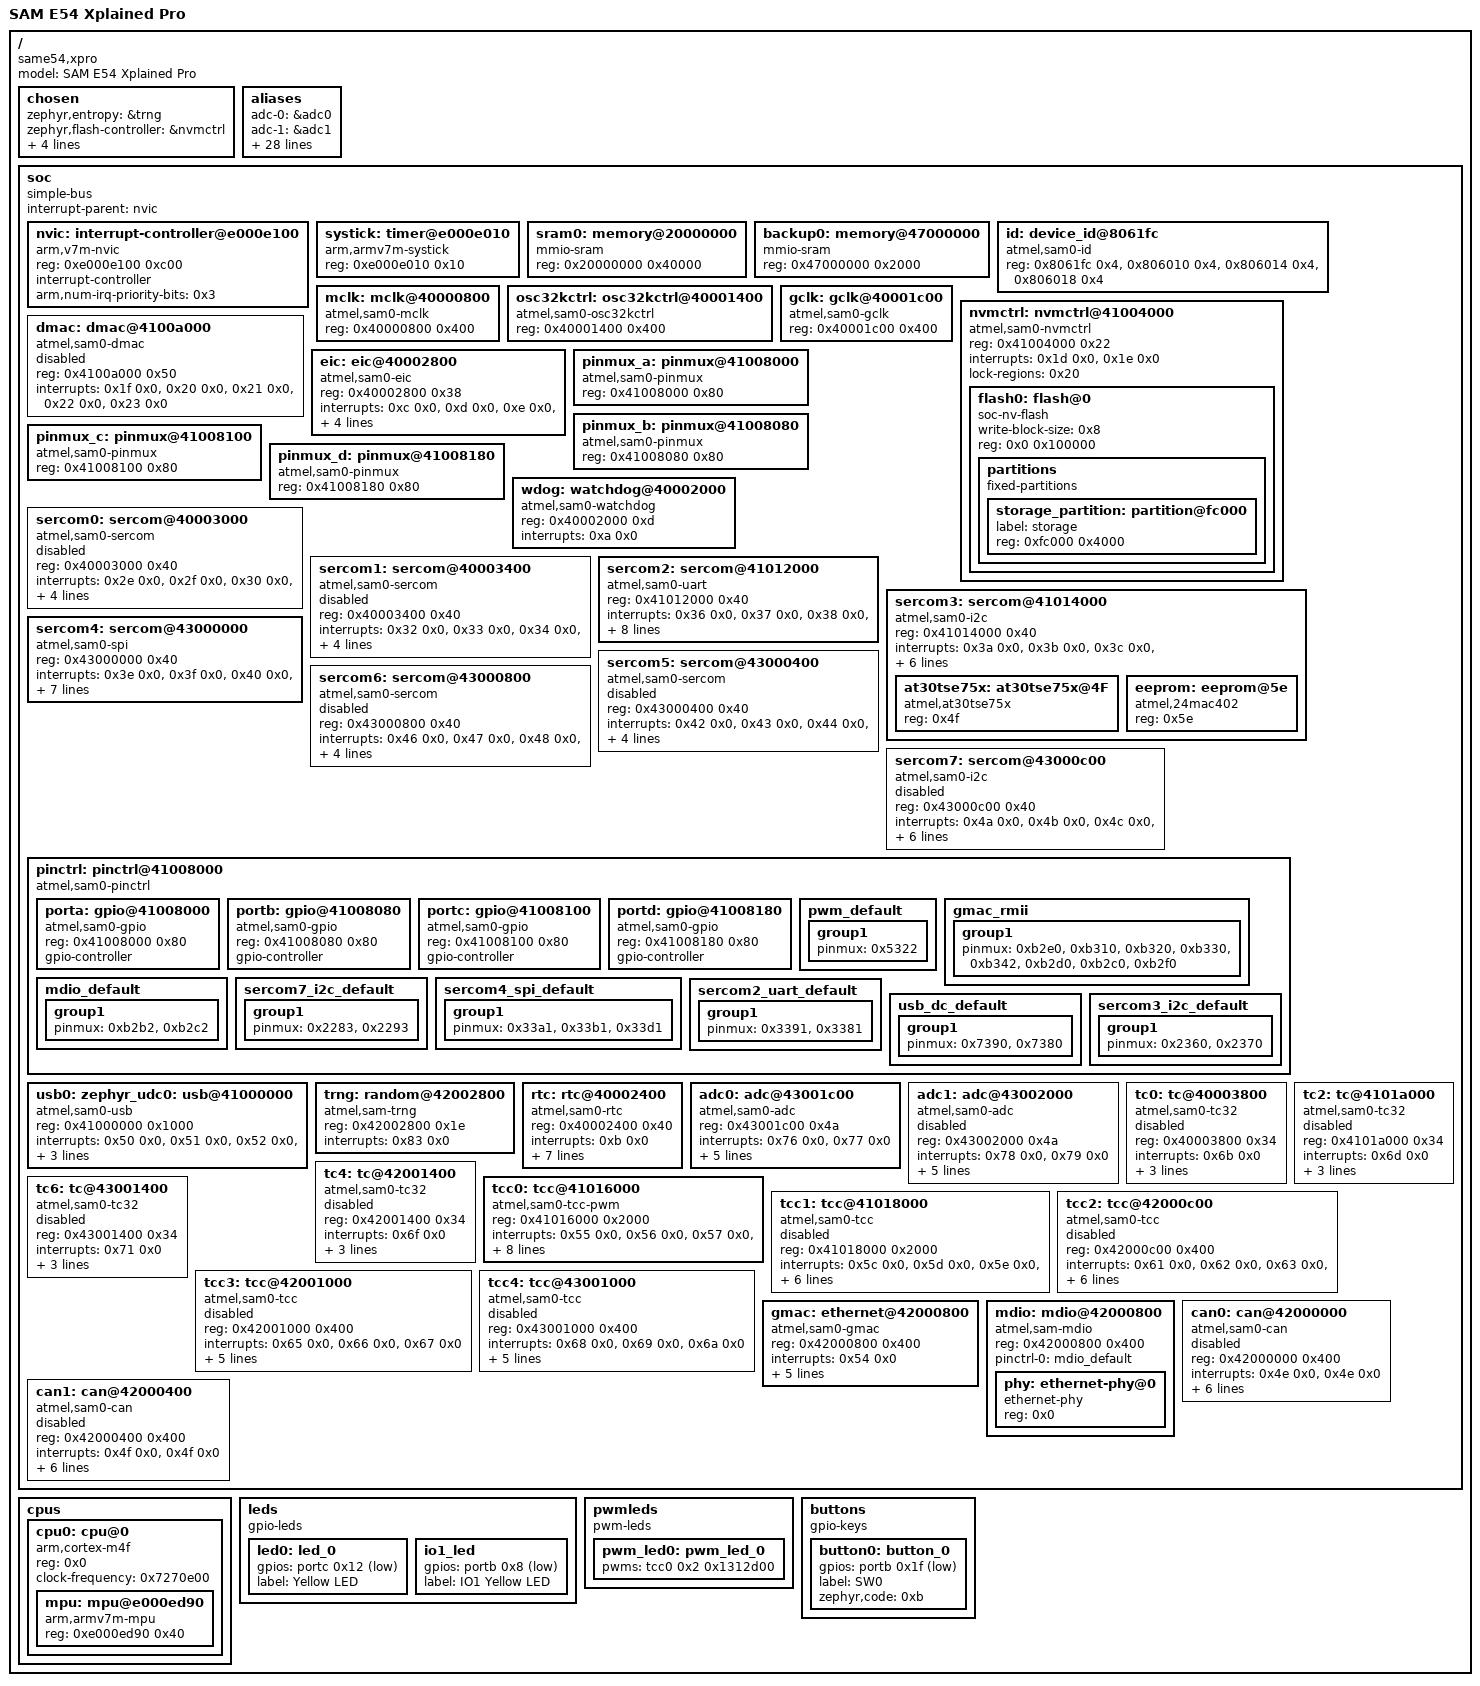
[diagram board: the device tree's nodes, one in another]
/dts-v1/;

/* node '/' defined in zephyr/dts/common/skeleton.dtsi:9 */
/ {
	#address-cells = < 0x1 >;        /* in zephyr/dts/common/skeleton.dtsi:10 */
	#size-cells = < 0x1 >;           /* in zephyr/dts/common/skeleton.dtsi:11 */
	model = "SAM E54 Xplained Pro";  /* in zephyr/boards/atmel/sam0/same54_xpro/same54_xpro.dts:14 */
	compatible = "same54,xpro",
	             "atmel,same54p20a",
	             "atmel,same54";     /* in zephyr/boards/atmel/sam0/same54_xpro/same54_xpro.dts:15 */

	/* node '/chosen' defined in zephyr/dts/common/skeleton.dtsi:12 */
	chosen {
		zephyr,entropy = &trng;             /* in zephyr/dts/arm/atmel/samd5x.dtsi:51 */
		zephyr,flash-controller = &nvmctrl; /* in zephyr/dts/arm/atmel/samd5x.dtsi:52 */
		zephyr,console = &sercom2;          /* in zephyr/boards/atmel/sam0/same54_xpro/same54_xpro.dts:18 */
		zephyr,shell-uart = &sercom2;       /* in zephyr/boards/atmel/sam0/same54_xpro/same54_xpro.dts:19 */
		zephyr,sram = &sram0;               /* in zephyr/boards/atmel/sam0/same54_xpro/same54_xpro.dts:20 */
		zephyr,flash = &flash0;             /* in zephyr/boards/atmel/sam0/same54_xpro/same54_xpro.dts:21 */
	};

	/* node '/aliases' defined in zephyr/dts/common/skeleton.dtsi:13 */
	aliases {
		adc-0 = &adc0;        /* in zephyr/dts/arm/atmel/samd5x.dtsi:16 */
		adc-1 = &adc1;        /* in zephyr/dts/arm/atmel/samd5x.dtsi:17 */
		port-a = &porta;      /* in zephyr/dts/arm/atmel/samd5x.dtsi:19 */
		port-b = &portb;      /* in zephyr/dts/arm/atmel/samd5x.dtsi:20 */
		port-c = &portc;      /* in zephyr/dts/arm/atmel/samd5x.dtsi:21 */
		port-d = &portd;      /* in zephyr/dts/arm/atmel/samd5x.dtsi:22 */
		rtc = &rtc;           /* in zephyr/dts/arm/atmel/samd5x.dtsi:24 */
		sercom-0 = &sercom0;  /* in zephyr/dts/arm/atmel/samd5x.dtsi:26 */
		sercom-1 = &sercom1;  /* in zephyr/dts/arm/atmel/samd5x.dtsi:27 */
		sercom-2 = &sercom2;  /* in zephyr/dts/arm/atmel/samd5x.dtsi:28 */
		sercom-3 = &sercom3;  /* in zephyr/dts/arm/atmel/samd5x.dtsi:29 */
		sercom-4 = &sercom4;  /* in zephyr/dts/arm/atmel/samd5x.dtsi:30 */
		sercom-5 = &sercom5;  /* in zephyr/dts/arm/atmel/samd5x.dtsi:31 */
		sercom-6 = &sercom6;  /* in zephyr/dts/arm/atmel/samd5x.dtsi:32 */
		sercom-7 = &sercom7;  /* in zephyr/dts/arm/atmel/samd5x.dtsi:33 */
		tc-0 = &tc0;          /* in zephyr/dts/arm/atmel/samd5x.dtsi:35 */
		tc-2 = &tc2;          /* in zephyr/dts/arm/atmel/samd5x.dtsi:36 */
		tc-4 = &tc4;          /* in zephyr/dts/arm/atmel/samd5x.dtsi:37 */
		tc-6 = &tc6;          /* in zephyr/dts/arm/atmel/samd5x.dtsi:38 */
		tcc-0 = &tcc0;        /* in zephyr/dts/arm/atmel/samd5x.dtsi:40 */
		tcc-1 = &tcc1;        /* in zephyr/dts/arm/atmel/samd5x.dtsi:41 */
		tcc-2 = &tcc2;        /* in zephyr/dts/arm/atmel/samd5x.dtsi:42 */
		tcc-3 = &tcc3;        /* in zephyr/dts/arm/atmel/samd5x.dtsi:43 */
		tcc-4 = &tcc4;        /* in zephyr/dts/arm/atmel/samd5x.dtsi:44 */
		watchdog0 = &wdog;    /* in zephyr/dts/arm/atmel/samd5x.dtsi:46 */
		led0 = &led0;         /* in zephyr/boards/atmel/sam0/same54_xpro/same54_xpro.dts:26 */
		pwm-led0 = &pwm_led0; /* in zephyr/boards/atmel/sam0/same54_xpro/same54_xpro.dts:27 */
		sw0 = &button0;       /* in zephyr/boards/atmel/sam0/same54_xpro/same54_xpro.dts:28 */
		io1-led = &io1_led;   /* in temperature-web-app/app/boards/same54_xpro.overlay:55 */
		i2c-0 = &sercom3;     /* in temperature-web-app/app/boards/same54_xpro.overlay:56 */
	};

	/* node '/soc' defined in zephyr/dts/arm/armv7-m.dtsi:6 */
	soc {
		#address-cells = < 0x1 >;     /* in zephyr/dts/arm/armv7-m.dtsi:7 */
		#size-cells = < 0x1 >;        /* in zephyr/dts/arm/armv7-m.dtsi:8 */
		compatible = "simple-bus";    /* in zephyr/dts/arm/armv7-m.dtsi:9 */
		interrupt-parent = < &nvic >; /* in zephyr/dts/arm/armv7-m.dtsi:10 */
		ranges;                       /* in zephyr/dts/arm/armv7-m.dtsi:11 */

		/* node '/soc/interrupt-controller@e000e100' defined in zephyr/dts/arm/armv7-m.dtsi:13 */
		nvic: interrupt-controller@e000e100 {
			#address-cells = < 0x1 >;            /* in zephyr/dts/arm/armv7-m.dtsi:14 */
			compatible = "arm,v7m-nvic";         /* in zephyr/dts/arm/armv7-m.dtsi:15 */
			reg = < 0xe000e100 0xc00 >;          /* in zephyr/dts/arm/armv7-m.dtsi:16 */
			interrupt-controller;                /* in zephyr/dts/arm/armv7-m.dtsi:17 */
			#interrupt-cells = < 0x2 >;          /* in zephyr/dts/arm/armv7-m.dtsi:18 */
			arm,num-irq-priority-bits = < 0x3 >; /* in zephyr/dts/arm/atmel/samd5x.dtsi:509 */
			phandle = < 0x1 >;                   /* in zephyr/dts/arm/armv7-m.dtsi:10 */
		};

		/* node '/soc/timer@e000e010' defined in zephyr/dts/arm/armv7-m.dtsi:21 */
		systick: timer@e000e010 {
			compatible = "arm,armv7m-systick"; /* in zephyr/dts/arm/armv7-m.dtsi:22 */
			reg = < 0xe000e010 0x10 >;         /* in zephyr/dts/arm/armv7-m.dtsi:23 */
		};

		/* node '/soc/memory@20000000' defined in zephyr/dts/arm/atmel/samd5x.dtsi:76 */
		sram0: memory@20000000 {
			compatible = "mmio-sram";     /* in zephyr/dts/arm/atmel/samd5x.dtsi:77 */
			reg = < 0x20000000 0x40000 >; /* in zephyr/dts/arm/atmel/same5xx20.dtsi:19 */
		};

		/* node '/soc/memory@47000000' defined in zephyr/dts/arm/atmel/samd5x.dtsi:81 */
		backup0: memory@47000000 {
			compatible = "mmio-sram";    /* in zephyr/dts/arm/atmel/samd5x.dtsi:82 */
			reg = < 0x47000000 0x2000 >; /* in zephyr/dts/arm/atmel/samd5x.dtsi:83 */
		};

		/* node '/soc/device_id@8061fc' defined in zephyr/dts/arm/atmel/samd5x.dtsi:86 */
		id: device_id@8061fc {
			compatible = "atmel,sam0-id"; /* in zephyr/dts/arm/atmel/samd5x.dtsi:87 */
			reg = < 0x8061fc 0x4 >,
			      < 0x806010 0x4 >,
			      < 0x806014 0x4 >,
			      < 0x806018 0x4 >;       /* in zephyr/dts/arm/atmel/samd5x.dtsi:88 */
		};

		/* node '/soc/mclk@40000800' defined in zephyr/dts/arm/atmel/samd5x.dtsi:94 */
		mclk: mclk@40000800 {
			compatible = "atmel,sam0-mclk"; /* in zephyr/dts/arm/atmel/samd5x.dtsi:95 */
			reg = < 0x40000800 0x400 >;     /* in zephyr/dts/arm/atmel/samd5x.dtsi:96 */
			#clock-cells = < 0x2 >;         /* in zephyr/dts/arm/atmel/samd5x.dtsi:98 */
			phandle = < 0x3 >;              /* in zephyr/dts/arm/atmel/samd5x.dtsi:181 */
		};

		/* node '/soc/osc32kctrl@40001400' defined in zephyr/dts/arm/atmel/samd5x.dtsi:101 */
		osc32kctrl: osc32kctrl@40001400 {
			compatible = "atmel,sam0-osc32kctrl";  /* in zephyr/dts/arm/atmel/samd5x.dtsi:102 */
			reg = < 0x40001400 0x400 >;            /* in zephyr/dts/arm/atmel/samd5x.dtsi:103 */
			#clock-cells = < 0x0 >;                /* in zephyr/dts/arm/atmel/samd5x.dtsi:104 */
			#atmel,assigned-clock-cells = < 0x1 >; /* in zephyr/dts/arm/atmel/samd5x.dtsi:105 */
			phandle = < 0x9 >;                     /* in zephyr/dts/arm/atmel/samd5x.dtsi:332 */
		};

		/* node '/soc/gclk@40001c00' defined in zephyr/dts/arm/atmel/samd5x.dtsi:108 */
		gclk: gclk@40001c00 {
			compatible = "atmel,sam0-gclk";        /* in zephyr/dts/arm/atmel/samd5x.dtsi:109 */
			reg = < 0x40001c00 0x400 >;            /* in zephyr/dts/arm/atmel/samd5x.dtsi:110 */
			#clock-cells = < 0x1 >;                /* in zephyr/dts/arm/atmel/samd5x.dtsi:112 */
			#atmel,assigned-clock-cells = < 0x1 >; /* in zephyr/dts/arm/atmel/samd5x.dtsi:113 */
			phandle = < 0x2 >;                     /* in zephyr/dts/arm/atmel/samd5x.dtsi:181 */
		};

		/* node '/soc/nvmctrl@41004000' defined in zephyr/dts/arm/atmel/samd5x.dtsi:116 */
		nvmctrl: nvmctrl@41004000 {
			compatible = "atmel,sam0-nvmctrl"; /* in zephyr/dts/arm/atmel/samd5x.dtsi:117 */
			reg = < 0x41004000 0x22 >;         /* in zephyr/dts/arm/atmel/samd5x.dtsi:118 */
			interrupts = < 0x1d 0x0 >,
			             < 0x1e 0x0 >;         /* in zephyr/dts/arm/atmel/samd5x.dtsi:119 */
			#address-cells = < 0x1 >;          /* in zephyr/dts/arm/atmel/samd5x.dtsi:121 */
			#size-cells = < 0x1 >;             /* in zephyr/dts/arm/atmel/samd5x.dtsi:122 */
			lock-regions = < 0x20 >;           /* in zephyr/dts/arm/atmel/samd5x.dtsi:124 */

			/* node '/soc/nvmctrl@41004000/flash@0' defined in zephyr/dts/arm/atmel/samd5x.dtsi:126 */
			flash0: flash@0 {
				compatible = "soc-nv-flash"; /* in zephyr/dts/arm/atmel/samd5x.dtsi:127 */
				write-block-size = < 0x8 >;  /* in zephyr/dts/arm/atmel/samd5x.dtsi:129 */
				reg = < 0x0 0x100000 >;      /* in zephyr/dts/arm/atmel/same5xx20.dtsi:14 */

				/* node '/soc/nvmctrl@41004000/flash@0/partitions' defined in zephyr/boards/atmel/sam0/same54_xpro/same54_xpro.dts:156 */
				partitions {
					compatible = "fixed-partitions"; /* in zephyr/boards/atmel/sam0/same54_xpro/same54_xpro.dts:157 */
					#address-cells = < 0x1 >;        /* in zephyr/boards/atmel/sam0/same54_xpro/same54_xpro.dts:158 */
					#size-cells = < 0x1 >;           /* in zephyr/boards/atmel/sam0/same54_xpro/same54_xpro.dts:159 */

					/* node '/soc/nvmctrl@41004000/flash@0/partitions/partition@fc000' defined in zephyr/boards/atmel/sam0/same54_xpro/same54_xpro.dts:166 */
					storage_partition: partition@fc000 {
						label = "storage";        /* in zephyr/boards/atmel/sam0/same54_xpro/same54_xpro.dts:167 */
						reg = < 0xfc000 0x4000 >; /* in zephyr/boards/atmel/sam0/same54_xpro/same54_xpro.dts:168 */
					};
				};
			};
		};

		/* node '/soc/dmac@4100a000' defined in zephyr/dts/arm/atmel/samd5x.dtsi:133 */
		dmac: dmac@4100a000 {
			compatible = "atmel,sam0-dmac"; /* in zephyr/dts/arm/atmel/samd5x.dtsi:134 */
			reg = < 0x4100a000 0x50 >;      /* in zephyr/dts/arm/atmel/samd5x.dtsi:135 */
			interrupts = < 0x1f 0x0 >,
			             < 0x20 0x0 >,
			             < 0x21 0x0 >,
			             < 0x22 0x0 >,
			             < 0x23 0x0 >;      /* in zephyr/dts/arm/atmel/samd5x.dtsi:136 */
			status = "disabled";            /* in zephyr/dts/arm/atmel/samd5x.dtsi:137 */
			#dma-cells = < 0x2 >;           /* in zephyr/dts/arm/atmel/samd5x.dtsi:139 */
		};

		/* node '/soc/eic@40002800' defined in zephyr/dts/arm/atmel/samd5x.dtsi:142 */
		eic: eic@40002800 {
			compatible = "atmel,sam0-eic"; /* in zephyr/dts/arm/atmel/samd5x.dtsi:143 */
			reg = < 0x40002800 0x38 >;     /* in zephyr/dts/arm/atmel/samd5x.dtsi:144 */
			interrupts = < 0xc 0x0 >,
			             < 0xd 0x0 >,
			             < 0xe 0x0 >,
			             < 0xf 0x0 >,
			             < 0x10 0x0 >,
			             < 0x11 0x0 >,
			             < 0x12 0x0 >,
			             < 0x13 0x0 >,
			             < 0x14 0x0 >,
			             < 0x15 0x0 >,
			             < 0x16 0x0 >,
			             < 0x17 0x0 >,
			             < 0x18 0x0 >,
			             < 0x19 0x0 >,
			             < 0x1a 0x0 >,
			             < 0x1b 0x0 >;     /* in zephyr/dts/arm/atmel/samd5x.dtsi:145 */
		};

		/* node '/soc/pinmux@41008000' defined in zephyr/dts/arm/atmel/samd5x.dtsi:151 */
		pinmux_a: pinmux@41008000 {
			compatible = "atmel,sam0-pinmux"; /* in zephyr/dts/arm/atmel/samd5x.dtsi:152 */
			reg = < 0x41008000 0x80 >;        /* in zephyr/dts/arm/atmel/samd5x.dtsi:153 */
		};

		/* node '/soc/pinmux@41008080' defined in zephyr/dts/arm/atmel/samd5x.dtsi:156 */
		pinmux_b: pinmux@41008080 {
			compatible = "atmel,sam0-pinmux"; /* in zephyr/dts/arm/atmel/samd5x.dtsi:157 */
			reg = < 0x41008080 0x80 >;        /* in zephyr/dts/arm/atmel/samd5x.dtsi:158 */
		};

		/* node '/soc/pinmux@41008100' defined in zephyr/dts/arm/atmel/samd5x.dtsi:161 */
		pinmux_c: pinmux@41008100 {
			compatible = "atmel,sam0-pinmux"; /* in zephyr/dts/arm/atmel/samd5x.dtsi:162 */
			reg = < 0x41008100 0x80 >;        /* in zephyr/dts/arm/atmel/samd5x.dtsi:163 */
		};

		/* node '/soc/pinmux@41008180' defined in zephyr/dts/arm/atmel/samd5x.dtsi:166 */
		pinmux_d: pinmux@41008180 {
			compatible = "atmel,sam0-pinmux"; /* in zephyr/dts/arm/atmel/samd5x.dtsi:167 */
			reg = < 0x41008180 0x80 >;        /* in zephyr/dts/arm/atmel/samd5x.dtsi:168 */
		};

		/* node '/soc/watchdog@40002000' defined in zephyr/dts/arm/atmel/samd5x.dtsi:171 */
		wdog: watchdog@40002000 {
			compatible = "atmel,sam0-watchdog"; /* in zephyr/dts/arm/atmel/samd5x.dtsi:172 */
			reg = < 0x40002000 0xd >;           /* in zephyr/dts/arm/atmel/samd5x.dtsi:173 */
			interrupts = < 0xa 0x0 >;           /* in zephyr/dts/arm/atmel/samd5x.dtsi:174 */
		};

		/* node '/soc/sercom@40003000' defined in zephyr/dts/arm/atmel/samd5x.dtsi:177 */
		sercom0: sercom@40003000 {
			compatible = "atmel,sam0-sercom";      /* in zephyr/dts/arm/atmel/samd5x.dtsi:178 */
			reg = < 0x40003000 0x40 >;             /* in zephyr/dts/arm/atmel/samd5x.dtsi:179 */
			interrupts = < 0x2e 0x0 >,
			             < 0x2f 0x0 >,
			             < 0x30 0x0 >,
			             < 0x31 0x0 >;             /* in zephyr/dts/arm/atmel/samd5x.dtsi:180 */
			clocks = < &gclk 0x7 >,
			         < &mclk 0x14 0xc >;           /* in zephyr/dts/arm/atmel/samd5x.dtsi:181 */
			clock-names = "GCLK",
			              "MCLK";                  /* in zephyr/dts/arm/atmel/samd5x.dtsi:182 */
			atmel,assigned-clocks = < &gclk 0x0 >; /* in zephyr/dts/arm/atmel/samd5x.dtsi:183 */
			atmel,assigned-clock-names = "GCLK";   /* in zephyr/dts/arm/atmel/samd5x.dtsi:184 */
			status = "disabled";                   /* in zephyr/dts/arm/atmel/samd5x.dtsi:185 */
		};

		/* node '/soc/sercom@40003400' defined in zephyr/dts/arm/atmel/samd5x.dtsi:188 */
		sercom1: sercom@40003400 {
			compatible = "atmel,sam0-sercom";      /* in zephyr/dts/arm/atmel/samd5x.dtsi:189 */
			reg = < 0x40003400 0x40 >;             /* in zephyr/dts/arm/atmel/samd5x.dtsi:190 */
			interrupts = < 0x32 0x0 >,
			             < 0x33 0x0 >,
			             < 0x34 0x0 >,
			             < 0x35 0x0 >;             /* in zephyr/dts/arm/atmel/samd5x.dtsi:191 */
			clocks = < &gclk 0x8 >,
			         < &mclk 0x14 0xd >;           /* in zephyr/dts/arm/atmel/samd5x.dtsi:192 */
			clock-names = "GCLK",
			              "MCLK";                  /* in zephyr/dts/arm/atmel/samd5x.dtsi:193 */
			atmel,assigned-clocks = < &gclk 0x0 >; /* in zephyr/dts/arm/atmel/samd5x.dtsi:194 */
			atmel,assigned-clock-names = "GCLK";   /* in zephyr/dts/arm/atmel/samd5x.dtsi:195 */
			status = "disabled";                   /* in zephyr/dts/arm/atmel/samd5x.dtsi:196 */
		};

		/* node '/soc/sercom@41012000' defined in zephyr/dts/arm/atmel/samd5x.dtsi:199 */
		sercom2: sercom@41012000 {
			reg = < 0x41012000 0x40 >;             /* in zephyr/dts/arm/atmel/samd5x.dtsi:201 */
			interrupts = < 0x36 0x0 >,
			             < 0x37 0x0 >,
			             < 0x38 0x0 >,
			             < 0x39 0x0 >;             /* in zephyr/dts/arm/atmel/samd5x.dtsi:202 */
			clocks = < &gclk 0x17 >,
			         < &mclk 0x18 0x9 >;           /* in zephyr/dts/arm/atmel/samd5x.dtsi:203 */
			clock-names = "GCLK",
			              "MCLK";                  /* in zephyr/dts/arm/atmel/samd5x.dtsi:204 */
			atmel,assigned-clocks = < &gclk 0x0 >; /* in zephyr/dts/arm/atmel/samd5x.dtsi:205 */
			atmel,assigned-clock-names = "GCLK";   /* in zephyr/dts/arm/atmel/samd5x.dtsi:206 */
			status = "okay";                       /* in zephyr/boards/atmel/sam0/same54_xpro/same54_xpro.dts:81 */
			compatible = "atmel,sam0-uart";        /* in zephyr/boards/atmel/sam0/same54_xpro/same54_xpro.dts:82 */
			current-speed = < 0x1c200 >;           /* in zephyr/boards/atmel/sam0/same54_xpro/same54_xpro.dts:83 */
			rxpo = < 0x1 >;                        /* in zephyr/boards/atmel/sam0/same54_xpro/same54_xpro.dts:84 */
			txpo = < 0x0 >;                        /* in zephyr/boards/atmel/sam0/same54_xpro/same54_xpro.dts:85 */
			#address-cells = < 0x1 >;              /* in zephyr/boards/atmel/sam0/same54_xpro/same54_xpro.dts:86 */
			#size-cells = < 0x0 >;                 /* in zephyr/boards/atmel/sam0/same54_xpro/same54_xpro.dts:87 */
			pinctrl-0 = < &sercom2_uart_default >; /* in zephyr/boards/atmel/sam0/same54_xpro/same54_xpro.dts:89 */
			pinctrl-names = "default";             /* in zephyr/boards/atmel/sam0/same54_xpro/same54_xpro.dts:90 */
		};

		/* node '/soc/sercom@41014000' defined in zephyr/dts/arm/atmel/samd5x.dtsi:210 */
		sercom3: sercom@41014000 {
			reg = < 0x41014000 0x40 >;             /* in zephyr/dts/arm/atmel/samd5x.dtsi:212 */
			interrupts = < 0x3a 0x0 >,
			             < 0x3b 0x0 >,
			             < 0x3c 0x0 >,
			             < 0x3d 0x0 >;             /* in zephyr/dts/arm/atmel/samd5x.dtsi:213 */
			clocks = < &gclk 0x18 >,
			         < &mclk 0x18 0xa >;           /* in zephyr/dts/arm/atmel/samd5x.dtsi:214 */
			clock-names = "GCLK",
			              "MCLK";                  /* in zephyr/dts/arm/atmel/samd5x.dtsi:215 */
			atmel,assigned-clocks = < &gclk 0x0 >; /* in zephyr/dts/arm/atmel/samd5x.dtsi:216 */
			atmel,assigned-clock-names = "GCLK";   /* in zephyr/dts/arm/atmel/samd5x.dtsi:217 */
			status = "okay";                       /* in temperature-web-app/app/boards/same54_xpro.overlay:22 */
			compatible = "atmel,sam0-i2c";         /* in temperature-web-app/app/boards/same54_xpro.overlay:23 */
			clock-frequency = < 0x61a80 >;         /* in temperature-web-app/app/boards/same54_xpro.overlay:24 */
			#address-cells = < 0x1 >;              /* in temperature-web-app/app/boards/same54_xpro.overlay:25 */
			#size-cells = < 0x0 >;                 /* in temperature-web-app/app/boards/same54_xpro.overlay:26 */
			pinctrl-0 = < &sercom3_i2c_default >;  /* in temperature-web-app/app/boards/same54_xpro.overlay:27 */
			pinctrl-names = "default";             /* in temperature-web-app/app/boards/same54_xpro.overlay:28 */

			/* node '/soc/sercom@41014000/at30tse75x@4F' defined in temperature-web-app/app/boards/same54_xpro.overlay:31 */
			at30tse75x: at30tse75x@4F {
				compatible = "atmel,at30tse75x"; /* in temperature-web-app/app/boards/same54_xpro.overlay:32 */
				reg = < 0x4f >;                  /* in temperature-web-app/app/boards/same54_xpro.overlay:33 */
			};

			/* node '/soc/sercom@41014000/eeprom@5e' defined in temperature-web-app/app/boards/same54_xpro.overlay:36 */
			eeprom: eeprom@5e {
				compatible = "atmel,24mac402"; /* in temperature-web-app/app/boards/same54_xpro.overlay:37 */
				reg = < 0x5e >;                /* in temperature-web-app/app/boards/same54_xpro.overlay:38 */
				phandle = < 0xc >;             /* in zephyr/boards/atmel/sam0/same54_xpro/same54_xpro.dts:138 */
			};
		};

		/* node '/soc/sercom@43000000' defined in zephyr/dts/arm/atmel/samd5x.dtsi:221 */
		sercom4: sercom@43000000 {
			reg = < 0x43000000 0x40 >;             /* in zephyr/dts/arm/atmel/samd5x.dtsi:223 */
			interrupts = < 0x3e 0x0 >,
			             < 0x3f 0x0 >,
			             < 0x40 0x0 >,
			             < 0x41 0x0 >;             /* in zephyr/dts/arm/atmel/samd5x.dtsi:224 */
			clocks = < &gclk 0x22 >,
			         < &mclk 0x20 0x0 >;           /* in zephyr/dts/arm/atmel/samd5x.dtsi:225 */
			clock-names = "GCLK",
			              "MCLK";                  /* in zephyr/dts/arm/atmel/samd5x.dtsi:226 */
			atmel,assigned-clocks = < &gclk 0x0 >; /* in zephyr/dts/arm/atmel/samd5x.dtsi:227 */
			atmel,assigned-clock-names = "GCLK";   /* in zephyr/dts/arm/atmel/samd5x.dtsi:228 */
			status = "okay";                       /* in zephyr/boards/atmel/sam0/same54_xpro/same54_xpro.dts:94 */
			compatible = "atmel,sam0-spi";         /* in zephyr/boards/atmel/sam0/same54_xpro/same54_xpro.dts:95 */
			dipo = < 0x3 >;                        /* in zephyr/boards/atmel/sam0/same54_xpro/same54_xpro.dts:96 */
			dopo = < 0x0 >;                        /* in zephyr/boards/atmel/sam0/same54_xpro/same54_xpro.dts:97 */
			#address-cells = < 0x1 >;              /* in zephyr/boards/atmel/sam0/same54_xpro/same54_xpro.dts:98 */
			#size-cells = < 0x0 >;                 /* in zephyr/boards/atmel/sam0/same54_xpro/same54_xpro.dts:99 */
			pinctrl-0 = < &sercom4_spi_default >;  /* in zephyr/boards/atmel/sam0/same54_xpro/same54_xpro.dts:101 */
			pinctrl-names = "default";             /* in zephyr/boards/atmel/sam0/same54_xpro/same54_xpro.dts:102 */
		};

		/* node '/soc/sercom@43000400' defined in zephyr/dts/arm/atmel/samd5x.dtsi:232 */
		sercom5: sercom@43000400 {
			compatible = "atmel,sam0-sercom";      /* in zephyr/dts/arm/atmel/samd5x.dtsi:233 */
			reg = < 0x43000400 0x40 >;             /* in zephyr/dts/arm/atmel/samd5x.dtsi:234 */
			interrupts = < 0x42 0x0 >,
			             < 0x43 0x0 >,
			             < 0x44 0x0 >,
			             < 0x45 0x0 >;             /* in zephyr/dts/arm/atmel/samd5x.dtsi:235 */
			clocks = < &gclk 0x23 >,
			         < &mclk 0x20 0x1 >;           /* in zephyr/dts/arm/atmel/samd5x.dtsi:236 */
			clock-names = "GCLK",
			              "MCLK";                  /* in zephyr/dts/arm/atmel/samd5x.dtsi:237 */
			atmel,assigned-clocks = < &gclk 0x0 >; /* in zephyr/dts/arm/atmel/samd5x.dtsi:238 */
			atmel,assigned-clock-names = "GCLK";   /* in zephyr/dts/arm/atmel/samd5x.dtsi:239 */
			status = "disabled";                   /* in zephyr/dts/arm/atmel/samd5x.dtsi:240 */
		};

		/* node '/soc/sercom@43000800' defined in zephyr/dts/arm/atmel/samd5x.dtsi:243 */
		sercom6: sercom@43000800 {
			compatible = "atmel,sam0-sercom";      /* in zephyr/dts/arm/atmel/samd5x.dtsi:244 */
			reg = < 0x43000800 0x40 >;             /* in zephyr/dts/arm/atmel/samd5x.dtsi:245 */
			interrupts = < 0x46 0x0 >,
			             < 0x47 0x0 >,
			             < 0x48 0x0 >,
			             < 0x49 0x0 >;             /* in zephyr/dts/arm/atmel/samd5x.dtsi:246 */
			clocks = < &gclk 0x24 >,
			         < &mclk 0x20 0x2 >;           /* in zephyr/dts/arm/atmel/samd5x.dtsi:247 */
			clock-names = "GCLK",
			              "MCLK";                  /* in zephyr/dts/arm/atmel/samd5x.dtsi:248 */
			atmel,assigned-clocks = < &gclk 0x0 >; /* in zephyr/dts/arm/atmel/samd5x.dtsi:249 */
			atmel,assigned-clock-names = "GCLK";   /* in zephyr/dts/arm/atmel/samd5x.dtsi:250 */
			status = "disabled";                   /* in zephyr/dts/arm/atmel/samd5x.dtsi:251 */
		};

		/* node '/soc/sercom@43000c00' defined in zephyr/dts/arm/atmel/samd5x.dtsi:254 */
		sercom7: sercom@43000c00 {
			reg = < 0x43000c00 0x40 >;             /* in zephyr/dts/arm/atmel/samd5x.dtsi:256 */
			interrupts = < 0x4a 0x0 >,
			             < 0x4b 0x0 >,
			             < 0x4c 0x0 >,
			             < 0x4d 0x0 >;             /* in zephyr/dts/arm/atmel/samd5x.dtsi:257 */
			clocks = < &gclk 0x25 >,
			         < &mclk 0x20 0x3 >;           /* in zephyr/dts/arm/atmel/samd5x.dtsi:258 */
			clock-names = "GCLK",
			              "MCLK";                  /* in zephyr/dts/arm/atmel/samd5x.dtsi:259 */
			atmel,assigned-clocks = < &gclk 0x0 >; /* in zephyr/dts/arm/atmel/samd5x.dtsi:260 */
			atmel,assigned-clock-names = "GCLK";   /* in zephyr/dts/arm/atmel/samd5x.dtsi:261 */
			clock-frequency = < 0x61a80 >;         /* in zephyr/boards/atmel/sam0/same54_xpro/same54_xpro.dts:108 */
			#address-cells = < 0x1 >;              /* in zephyr/boards/atmel/sam0/same54_xpro/same54_xpro.dts:109 */
			#size-cells = < 0x0 >;                 /* in zephyr/boards/atmel/sam0/same54_xpro/same54_xpro.dts:110 */
			pinctrl-0 = < &sercom7_i2c_default >;  /* in zephyr/boards/atmel/sam0/same54_xpro/same54_xpro.dts:112 */
			pinctrl-names = "default";             /* in zephyr/boards/atmel/sam0/same54_xpro/same54_xpro.dts:113 */
			status = "disabled";                   /* in temperature-web-app/app/boards/same54_xpro.overlay:3 */
			compatible = "atmel,sam0-i2c";         /* in temperature-web-app/app/boards/same54_xpro.overlay:4 */
		};

		/* node '/soc/pinctrl@41008000' defined in zephyr/dts/arm/atmel/samd5x.dtsi:265 */
		pinctrl: pinctrl@41008000 {
			compatible = "atmel,sam0-pinctrl";        /* in zephyr/dts/arm/atmel/samd5x.dtsi:266 */
			ranges = < 0x41008000 0x41008000 0x200 >; /* in zephyr/dts/arm/atmel/samd5x.dtsi:267 */
			#address-cells = < 0x1 >;                 /* in zephyr/dts/arm/atmel/samd5x.dtsi:269 */
			#size-cells = < 0x1 >;                    /* in zephyr/dts/arm/atmel/samd5x.dtsi:270 */

			/* node '/soc/pinctrl@41008000/gpio@41008000' defined in zephyr/dts/arm/atmel/samd5x.dtsi:272 */
			porta: gpio@41008000 {
				compatible = "atmel,sam0-gpio"; /* in zephyr/dts/arm/atmel/samd5x.dtsi:273 */
				reg = < 0x41008000 0x80 >;      /* in zephyr/dts/arm/atmel/samd5x.dtsi:274 */
				#atmel,pin-cells = < 0x2 >;     /* in zephyr/dts/arm/atmel/samd5x.dtsi:276 */
				#gpio-cells = < 0x2 >;          /* in zephyr/dts/arm/atmel/samd5x.dtsi:277 */
				gpio-controller;                /* in zephyr/dts/arm/atmel/samd5x.dtsi:279 */
			};

			/* node '/soc/pinctrl@41008000/gpio@41008080' defined in zephyr/dts/arm/atmel/samd5x.dtsi:282 */
			portb: gpio@41008080 {
				compatible = "atmel,sam0-gpio"; /* in zephyr/dts/arm/atmel/samd5x.dtsi:283 */
				reg = < 0x41008080 0x80 >;      /* in zephyr/dts/arm/atmel/samd5x.dtsi:284 */
				#atmel,pin-cells = < 0x2 >;     /* in zephyr/dts/arm/atmel/samd5x.dtsi:286 */
				#gpio-cells = < 0x2 >;          /* in zephyr/dts/arm/atmel/samd5x.dtsi:287 */
				gpio-controller;                /* in zephyr/dts/arm/atmel/samd5x.dtsi:289 */
				phandle = < 0x10 >;             /* in temperature-web-app/app/boards/same54_xpro.overlay:48 */
			};

			/* node '/soc/pinctrl@41008000/gpio@41008100' defined in zephyr/dts/arm/atmel/samd5x.dtsi:292 */
			portc: gpio@41008100 {
				compatible = "atmel,sam0-gpio"; /* in zephyr/dts/arm/atmel/samd5x.dtsi:293 */
				reg = < 0x41008100 0x80 >;      /* in zephyr/dts/arm/atmel/samd5x.dtsi:294 */
				#atmel,pin-cells = < 0x2 >;     /* in zephyr/dts/arm/atmel/samd5x.dtsi:296 */
				#gpio-cells = < 0x2 >;          /* in zephyr/dts/arm/atmel/samd5x.dtsi:297 */
				gpio-controller;                /* in zephyr/dts/arm/atmel/samd5x.dtsi:299 */
				phandle = < 0xf >;              /* in zephyr/boards/atmel/sam0/same54_xpro/same54_xpro.dts:35 */
			};

			/* node '/soc/pinctrl@41008000/gpio@41008180' defined in zephyr/dts/arm/atmel/samd5x.dtsi:302 */
			portd: gpio@41008180 {
				compatible = "atmel,sam0-gpio"; /* in zephyr/dts/arm/atmel/samd5x.dtsi:303 */
				reg = < 0x41008180 0x80 >;      /* in zephyr/dts/arm/atmel/samd5x.dtsi:304 */
				#atmel,pin-cells = < 0x2 >;     /* in zephyr/dts/arm/atmel/samd5x.dtsi:306 */
				#gpio-cells = < 0x2 >;          /* in zephyr/dts/arm/atmel/samd5x.dtsi:307 */
				gpio-controller;                /* in zephyr/dts/arm/atmel/samd5x.dtsi:309 */
			};

			/* node '/soc/pinctrl@41008000/pwm_default' defined in zephyr/boards/atmel/sam0/same54_xpro/same54_xpro-pinctrl.dtsi:9 */
			pwm_default: pwm_default {
				phandle = < 0xa >; /* in zephyr/boards/atmel/sam0/same54_xpro/same54_xpro.dts:68 */

				/* node '/soc/pinctrl@41008000/pwm_default/group1' defined in zephyr/boards/atmel/sam0/same54_xpro/same54_xpro-pinctrl.dtsi:10 */
				group1 {
					pinmux = < 0x5322 >; /* in zephyr/boards/atmel/sam0/same54_xpro/same54_xpro-pinctrl.dtsi:11 */
				};
			};

			/* node '/soc/pinctrl@41008000/gmac_rmii' defined in zephyr/boards/atmel/sam0/same54_xpro/same54_xpro-pinctrl.dtsi:15 */
			gmac_rmii: gmac_rmii {
				phandle = < 0xb >; /* in zephyr/boards/atmel/sam0/same54_xpro/same54_xpro.dts:135 */

				/* node '/soc/pinctrl@41008000/gmac_rmii/group1' defined in zephyr/boards/atmel/sam0/same54_xpro/same54_xpro-pinctrl.dtsi:16 */
				group1 {
					pinmux = < 0xb2e0 >,
					         < 0xb310 >,
					         < 0xb320 >,
					         < 0xb330 >,
					         < 0xb342 >,
					         < 0xb2d0 >,
					         < 0xb2c0 >,
					         < 0xb2f0 >; /* in zephyr/boards/atmel/sam0/same54_xpro/same54_xpro-pinctrl.dtsi:17 */
				};
			};

			/* node '/soc/pinctrl@41008000/mdio_default' defined in zephyr/boards/atmel/sam0/same54_xpro/same54_xpro-pinctrl.dtsi:28 */
			mdio_default: mdio_default {
				phandle = < 0xe >; /* in zephyr/boards/atmel/sam0/same54_xpro/same54_xpro.dts:145 */

				/* node '/soc/pinctrl@41008000/mdio_default/group1' defined in zephyr/boards/atmel/sam0/same54_xpro/same54_xpro-pinctrl.dtsi:29 */
				group1 {
					pinmux = < 0xb2b2 >,
					         < 0xb2c2 >; /* in zephyr/boards/atmel/sam0/same54_xpro/same54_xpro-pinctrl.dtsi:30 */
				};
			};

			/* node '/soc/pinctrl@41008000/sercom7_i2c_default' defined in zephyr/boards/atmel/sam0/same54_xpro/same54_xpro-pinctrl.dtsi:35 */
			sercom7_i2c_default: sercom7_i2c_default {
				phandle = < 0x7 >; /* in zephyr/boards/atmel/sam0/same54_xpro/same54_xpro.dts:112 */

				/* node '/soc/pinctrl@41008000/sercom7_i2c_default/group1' defined in zephyr/boards/atmel/sam0/same54_xpro/same54_xpro-pinctrl.dtsi:36 */
				group1 {
					pinmux = < 0x2283 >,
					         < 0x2293 >; /* in zephyr/boards/atmel/sam0/same54_xpro/same54_xpro-pinctrl.dtsi:37 */
				};
			};

			/* node '/soc/pinctrl@41008000/sercom4_spi_default' defined in zephyr/boards/atmel/sam0/same54_xpro/same54_xpro-pinctrl.dtsi:42 */
			sercom4_spi_default: sercom4_spi_default {
				phandle = < 0x6 >; /* in zephyr/boards/atmel/sam0/same54_xpro/same54_xpro.dts:101 */

				/* node '/soc/pinctrl@41008000/sercom4_spi_default/group1' defined in zephyr/boards/atmel/sam0/same54_xpro/same54_xpro-pinctrl.dtsi:43 */
				group1 {
					pinmux = < 0x33a1 >,
					         < 0x33b1 >,
					         < 0x33d1 >; /* in zephyr/boards/atmel/sam0/same54_xpro/same54_xpro-pinctrl.dtsi:44 */
				};
			};

			/* node '/soc/pinctrl@41008000/sercom2_uart_default' defined in zephyr/boards/atmel/sam0/same54_xpro/same54_xpro-pinctrl.dtsi:50 */
			sercom2_uart_default: sercom2_uart_default {
				phandle = < 0x4 >; /* in zephyr/boards/atmel/sam0/same54_xpro/same54_xpro.dts:89 */

				/* node '/soc/pinctrl@41008000/sercom2_uart_default/group1' defined in zephyr/boards/atmel/sam0/same54_xpro/same54_xpro-pinctrl.dtsi:51 */
				group1 {
					pinmux = < 0x3391 >,
					         < 0x3381 >; /* in zephyr/boards/atmel/sam0/same54_xpro/same54_xpro-pinctrl.dtsi:52 */
				};
			};

			/* node '/soc/pinctrl@41008000/usb_dc_default' defined in zephyr/boards/atmel/sam0/same54_xpro/same54_xpro-pinctrl.dtsi:57 */
			usb_dc_default: usb_dc_default {
				phandle = < 0x8 >; /* in zephyr/boards/atmel/sam0/same54_xpro/same54_xpro.dts:128 */

				/* node '/soc/pinctrl@41008000/usb_dc_default/group1' defined in zephyr/boards/atmel/sam0/same54_xpro/same54_xpro-pinctrl.dtsi:58 */
				group1 {
					pinmux = < 0x7390 >,
					         < 0x7380 >; /* in zephyr/boards/atmel/sam0/same54_xpro/same54_xpro-pinctrl.dtsi:59 */
				};
			};

			/* node '/soc/pinctrl@41008000/sercom3_i2c_default' defined in temperature-web-app/app/boards/same54_xpro.overlay:11 */
			sercom3_i2c_default: sercom3_i2c_default {
				phandle = < 0x5 >; /* in temperature-web-app/app/boards/same54_xpro.overlay:27 */

				/* node '/soc/pinctrl@41008000/sercom3_i2c_default/group1' defined in temperature-web-app/app/boards/same54_xpro.overlay:12 */
				group1 {
					pinmux = < 0x2360 >,
					         < 0x2370 >; /* in temperature-web-app/app/boards/same54_xpro.overlay:13 */
				};
			};
		};

		/* node '/soc/usb@41000000' defined in zephyr/dts/arm/atmel/samd5x.dtsi:313 */
		usb0: zephyr_udc0: usb@41000000 {
			compatible = "atmel,sam0-usb";   /* in zephyr/dts/arm/atmel/samd5x.dtsi:314 */
			reg = < 0x41000000 0x1000 >;     /* in zephyr/dts/arm/atmel/samd5x.dtsi:315 */
			interrupts = < 0x50 0x0 >,
			             < 0x51 0x0 >,
			             < 0x52 0x0 >,
			             < 0x53 0x0 >;       /* in zephyr/dts/arm/atmel/samd5x.dtsi:316 */
			num-bidir-endpoints = < 0x8 >;   /* in zephyr/dts/arm/atmel/samd5x.dtsi:319 */
			status = "okay";                 /* in zephyr/boards/atmel/sam0/same54_xpro/same54_xpro.dts:126 */
			pinctrl-0 = < &usb_dc_default >; /* in zephyr/boards/atmel/sam0/same54_xpro/same54_xpro.dts:128 */
			pinctrl-names = "default";       /* in zephyr/boards/atmel/sam0/same54_xpro/same54_xpro.dts:129 */
		};

		/* node '/soc/random@42002800' defined in zephyr/dts/arm/atmel/samd5x.dtsi:322 */
		trng: random@42002800 {
			compatible = "atmel,sam-trng"; /* in zephyr/dts/arm/atmel/samd5x.dtsi:323 */
			reg = < 0x42002800 0x1e >;     /* in zephyr/dts/arm/atmel/samd5x.dtsi:324 */
			interrupts = < 0x83 0x0 >;     /* in zephyr/dts/arm/atmel/samd5x.dtsi:325 */
		};

		/* node '/soc/rtc@40002400' defined in zephyr/dts/arm/atmel/samd5x.dtsi:328 */
		rtc: rtc@40002400 {
			compatible = "atmel,sam0-rtc";               /* in zephyr/dts/arm/atmel/samd5x.dtsi:329 */
			reg = < 0x40002400 0x40 >;                   /* in zephyr/dts/arm/atmel/samd5x.dtsi:330 */
			interrupts = < 0xb 0x0 >;                    /* in zephyr/dts/arm/atmel/samd5x.dtsi:331 */
			clocks = < &osc32kctrl >,
			         < &mclk 0x14 0x9 >;                 /* in zephyr/dts/arm/atmel/samd5x.dtsi:332 */
			clock-names = "OSC32KCTRL",
			              "MCLK";                        /* in zephyr/dts/arm/atmel/samd5x.dtsi:333 */
			atmel,assigned-clock-names = "OSC32KCTRL";   /* in zephyr/dts/arm/atmel/samd5x.dtsi:335 */
			alarms-count = < 0x2 >;                      /* in zephyr/dts/arm/atmel/samd5x.dtsi:338 */
			cal-constant = < 0x100000 >;                 /* in zephyr/dts/arm/atmel/samd5x.dtsi:339 */
			status = "okay";                             /* in zephyr/boards/atmel/sam0/same54_xpro/same54_xpro.dts:73 */
			counter-mode = "clock";                      /* in zephyr/boards/atmel/sam0/same54_xpro/same54_xpro.dts:74 */
			prescaler = < 0x400 >;                       /* in zephyr/boards/atmel/sam0/same54_xpro/same54_xpro.dts:75 */
			atmel,assigned-clocks = < &osc32kctrl 0x4 >; /* in zephyr/boards/atmel/sam0/same54_xpro/same54_xpro.dts:77 */
		};

		/* node '/soc/adc@43001c00' defined in zephyr/dts/arm/atmel/samd5x.dtsi:342 */
		adc0: adc@43001c00 {
			compatible = "atmel,sam0-adc";         /* in zephyr/dts/arm/atmel/samd5x.dtsi:343 */
			reg = < 0x43001c00 0x4a >;             /* in zephyr/dts/arm/atmel/samd5x.dtsi:344 */
			interrupts = < 0x76 0x0 >,
			             < 0x77 0x0 >;             /* in zephyr/dts/arm/atmel/samd5x.dtsi:345 */
			interrupt-names = "overrun",
			                  "resrdy";            /* in zephyr/dts/arm/atmel/samd5x.dtsi:346 */
			clocks = < &gclk 0x28 >,
			         < &mclk 0x20 0x7 >;           /* in zephyr/dts/arm/atmel/samd5x.dtsi:347 */
			clock-names = "GCLK",
			              "MCLK";                  /* in zephyr/dts/arm/atmel/samd5x.dtsi:348 */
			atmel,assigned-clocks = < &gclk 0x2 >; /* in zephyr/dts/arm/atmel/samd5x.dtsi:356 */
			atmel,assigned-clock-names = "GCLK";   /* in zephyr/dts/arm/atmel/samd5x.dtsi:357 */
			#io-channel-cells = < 0x1 >;           /* in zephyr/dts/arm/atmel/samd5x.dtsi:361 */
			prescaler = < 0x4 >;                   /* in zephyr/dts/arm/atmel/samd5x.dtsi:363 */
			calib-offset = < 0x0 >;                /* in zephyr/dts/arm/atmel/samd5x.dtsi:364 */
			status = "okay";                       /* in zephyr/boards/atmel/sam0/same54_xpro/same54_xpro.dts:122 */
		};

		/* node '/soc/adc@43002000' defined in zephyr/dts/arm/atmel/samd5x.dtsi:367 */
		adc1: adc@43002000 {
			compatible = "atmel,sam0-adc";         /* in zephyr/dts/arm/atmel/samd5x.dtsi:368 */
			reg = < 0x43002000 0x4a >;             /* in zephyr/dts/arm/atmel/samd5x.dtsi:369 */
			interrupts = < 0x78 0x0 >,
			             < 0x79 0x0 >;             /* in zephyr/dts/arm/atmel/samd5x.dtsi:370 */
			interrupt-names = "overrun",
			                  "resrdy";            /* in zephyr/dts/arm/atmel/samd5x.dtsi:371 */
			clocks = < &gclk 0x29 >,
			         < &mclk 0x20 0x8 >;           /* in zephyr/dts/arm/atmel/samd5x.dtsi:372 */
			clock-names = "GCLK",
			              "MCLK";                  /* in zephyr/dts/arm/atmel/samd5x.dtsi:373 */
			atmel,assigned-clocks = < &gclk 0x2 >; /* in zephyr/dts/arm/atmel/samd5x.dtsi:381 */
			atmel,assigned-clock-names = "GCLK";   /* in zephyr/dts/arm/atmel/samd5x.dtsi:382 */
			status = "disabled";                   /* in zephyr/dts/arm/atmel/samd5x.dtsi:383 */
			#io-channel-cells = < 0x1 >;           /* in zephyr/dts/arm/atmel/samd5x.dtsi:385 */
			prescaler = < 0x4 >;                   /* in zephyr/dts/arm/atmel/samd5x.dtsi:387 */
			calib-offset = < 0xe >;                /* in zephyr/dts/arm/atmel/samd5x.dtsi:388 */
		};

		/* node '/soc/tc@40003800' defined in zephyr/dts/arm/atmel/samd5x.dtsi:391 */
		tc0: tc@40003800 {
			compatible = "atmel,sam0-tc32";        /* in zephyr/dts/arm/atmel/samd5x.dtsi:392 */
			reg = < 0x40003800 0x34 >;             /* in zephyr/dts/arm/atmel/samd5x.dtsi:393 */
			interrupts = < 0x6b 0x0 >;             /* in zephyr/dts/arm/atmel/samd5x.dtsi:394 */
			clocks = < &gclk 0x9 >,
			         < &mclk 0x14 0xe >;           /* in zephyr/dts/arm/atmel/samd5x.dtsi:395 */
			clock-names = "GCLK",
			              "MCLK";                  /* in zephyr/dts/arm/atmel/samd5x.dtsi:396 */
			atmel,assigned-clocks = < &gclk 0x0 >; /* in zephyr/dts/arm/atmel/samd5x.dtsi:397 */
			atmel,assigned-clock-names = "GCLK";   /* in zephyr/dts/arm/atmel/samd5x.dtsi:398 */
			status = "disabled";                   /* in zephyr/dts/arm/atmel/samd5x.dtsi:399 */
		};

		/* node '/soc/tc@4101a000' defined in zephyr/dts/arm/atmel/samd5x.dtsi:402 */
		tc2: tc@4101a000 {
			compatible = "atmel,sam0-tc32";        /* in zephyr/dts/arm/atmel/samd5x.dtsi:403 */
			reg = < 0x4101a000 0x34 >;             /* in zephyr/dts/arm/atmel/samd5x.dtsi:404 */
			interrupts = < 0x6d 0x0 >;             /* in zephyr/dts/arm/atmel/samd5x.dtsi:405 */
			clocks = < &gclk 0x1a >,
			         < &mclk 0x18 0xd >;           /* in zephyr/dts/arm/atmel/samd5x.dtsi:406 */
			clock-names = "GCLK",
			              "MCLK";                  /* in zephyr/dts/arm/atmel/samd5x.dtsi:407 */
			atmel,assigned-clocks = < &gclk 0x0 >; /* in zephyr/dts/arm/atmel/samd5x.dtsi:408 */
			atmel,assigned-clock-names = "GCLK";   /* in zephyr/dts/arm/atmel/samd5x.dtsi:409 */
			status = "disabled";                   /* in zephyr/dts/arm/atmel/samd5x.dtsi:410 */
		};

		/* node '/soc/tc@42001400' defined in zephyr/dts/arm/atmel/samd5x.dtsi:413 */
		tc4: tc@42001400 {
			compatible = "atmel,sam0-tc32";        /* in zephyr/dts/arm/atmel/samd5x.dtsi:414 */
			reg = < 0x42001400 0x34 >;             /* in zephyr/dts/arm/atmel/samd5x.dtsi:415 */
			interrupts = < 0x6f 0x0 >;             /* in zephyr/dts/arm/atmel/samd5x.dtsi:416 */
			clocks = < &gclk 0x1e >,
			         < &mclk 0x1c 0x5 >;           /* in zephyr/dts/arm/atmel/samd5x.dtsi:417 */
			clock-names = "GCLK",
			              "MCLK";                  /* in zephyr/dts/arm/atmel/samd5x.dtsi:418 */
			atmel,assigned-clocks = < &gclk 0x0 >; /* in zephyr/dts/arm/atmel/samd5x.dtsi:419 */
			atmel,assigned-clock-names = "GCLK";   /* in zephyr/dts/arm/atmel/samd5x.dtsi:420 */
			status = "disabled";                   /* in zephyr/dts/arm/atmel/samd5x.dtsi:421 */
		};

		/* node '/soc/tc@43001400' defined in zephyr/dts/arm/atmel/samd5x.dtsi:424 */
		tc6: tc@43001400 {
			compatible = "atmel,sam0-tc32";        /* in zephyr/dts/arm/atmel/samd5x.dtsi:425 */
			reg = < 0x43001400 0x34 >;             /* in zephyr/dts/arm/atmel/samd5x.dtsi:426 */
			interrupts = < 0x71 0x0 >;             /* in zephyr/dts/arm/atmel/samd5x.dtsi:427 */
			clocks = < &gclk 0x27 >,
			         < &mclk 0x20 0x5 >;           /* in zephyr/dts/arm/atmel/samd5x.dtsi:428 */
			clock-names = "GCLK",
			              "MCLK";                  /* in zephyr/dts/arm/atmel/samd5x.dtsi:429 */
			atmel,assigned-clocks = < &gclk 0x0 >; /* in zephyr/dts/arm/atmel/samd5x.dtsi:430 */
			atmel,assigned-clock-names = "GCLK";   /* in zephyr/dts/arm/atmel/samd5x.dtsi:431 */
			status = "disabled";                   /* in zephyr/dts/arm/atmel/samd5x.dtsi:432 */
		};

		/* node '/soc/tcc@41016000' defined in zephyr/dts/arm/atmel/samd5x.dtsi:435 */
		tcc0: tcc@41016000 {
			reg = < 0x41016000 0x2000 >;           /* in zephyr/dts/arm/atmel/samd5x.dtsi:437 */
			interrupts = < 0x55 0x0 >,
			             < 0x56 0x0 >,
			             < 0x57 0x0 >,
			             < 0x58 0x0 >,
			             < 0x59 0x0 >,
			             < 0x5a 0x0 >,
			             < 0x5b 0x0 >;             /* in zephyr/dts/arm/atmel/samd5x.dtsi:438 */
			clocks = < &gclk 0x19 >,
			         < &mclk 0x18 0xb >;           /* in zephyr/dts/arm/atmel/samd5x.dtsi:440 */
			clock-names = "GCLK",
			              "MCLK";                  /* in zephyr/dts/arm/atmel/samd5x.dtsi:441 */
			atmel,assigned-clocks = < &gclk 0x0 >; /* in zephyr/dts/arm/atmel/samd5x.dtsi:442 */
			atmel,assigned-clock-names = "GCLK";   /* in zephyr/dts/arm/atmel/samd5x.dtsi:443 */
			channels = < 0x6 >;                    /* in zephyr/dts/arm/atmel/samd5x.dtsi:446 */
			counter-size = < 0x18 >;               /* in zephyr/dts/arm/atmel/samd5x.dtsi:447 */
			status = "okay";                       /* in zephyr/boards/atmel/sam0/same54_xpro/same54_xpro.dts:62 */
			compatible = "atmel,sam0-tcc-pwm";     /* in zephyr/boards/atmel/sam0/same54_xpro/same54_xpro.dts:63 */
			prescaler = < 0x8 >;                   /* in zephyr/boards/atmel/sam0/same54_xpro/same54_xpro.dts:65 */
			#pwm-cells = < 0x2 >;                  /* in zephyr/boards/atmel/sam0/same54_xpro/same54_xpro.dts:66 */
			pinctrl-0 = < &pwm_default >;          /* in zephyr/boards/atmel/sam0/same54_xpro/same54_xpro.dts:68 */
			pinctrl-names = "default";             /* in zephyr/boards/atmel/sam0/same54_xpro/same54_xpro.dts:69 */
			phandle = < 0x11 >;                    /* in zephyr/boards/atmel/sam0/same54_xpro/same54_xpro.dts:43 */
		};

		/* node '/soc/tcc@41018000' defined in zephyr/dts/arm/atmel/samd5x.dtsi:450 */
		tcc1: tcc@41018000 {
			compatible = "atmel,sam0-tcc";         /* in zephyr/dts/arm/atmel/samd5x.dtsi:451 */
			reg = < 0x41018000 0x2000 >;           /* in zephyr/dts/arm/atmel/samd5x.dtsi:452 */
			interrupts = < 0x5c 0x0 >,
			             < 0x5d 0x0 >,
			             < 0x5e 0x0 >,
			             < 0x5f 0x0 >,
			             < 0x60 0x0 >;             /* in zephyr/dts/arm/atmel/samd5x.dtsi:453 */
			clocks = < &gclk 0x19 >,
			         < &mclk 0x18 0xc >;           /* in zephyr/dts/arm/atmel/samd5x.dtsi:454 */
			clock-names = "GCLK",
			              "MCLK";                  /* in zephyr/dts/arm/atmel/samd5x.dtsi:455 */
			atmel,assigned-clocks = < &gclk 0x0 >; /* in zephyr/dts/arm/atmel/samd5x.dtsi:456 */
			atmel,assigned-clock-names = "GCLK";   /* in zephyr/dts/arm/atmel/samd5x.dtsi:457 */
			status = "disabled";                   /* in zephyr/dts/arm/atmel/samd5x.dtsi:458 */
			channels = < 0x4 >;                    /* in zephyr/dts/arm/atmel/samd5x.dtsi:460 */
			counter-size = < 0x18 >;               /* in zephyr/dts/arm/atmel/samd5x.dtsi:461 */
		};

		/* node '/soc/tcc@42000c00' defined in zephyr/dts/arm/atmel/samd5x.dtsi:464 */
		tcc2: tcc@42000c00 {
			compatible = "atmel,sam0-tcc";         /* in zephyr/dts/arm/atmel/samd5x.dtsi:465 */
			reg = < 0x42000c00 0x400 >;            /* in zephyr/dts/arm/atmel/samd5x.dtsi:466 */
			interrupts = < 0x61 0x0 >,
			             < 0x62 0x0 >,
			             < 0x63 0x0 >,
			             < 0x64 0x0 >;             /* in zephyr/dts/arm/atmel/samd5x.dtsi:467 */
			clocks = < &gclk 0x1d >,
			         < &mclk 0x1c 0x3 >;           /* in zephyr/dts/arm/atmel/samd5x.dtsi:468 */
			clock-names = "GCLK",
			              "MCLK";                  /* in zephyr/dts/arm/atmel/samd5x.dtsi:469 */
			atmel,assigned-clocks = < &gclk 0x0 >; /* in zephyr/dts/arm/atmel/samd5x.dtsi:470 */
			atmel,assigned-clock-names = "GCLK";   /* in zephyr/dts/arm/atmel/samd5x.dtsi:471 */
			status = "disabled";                   /* in zephyr/dts/arm/atmel/samd5x.dtsi:472 */
			channels = < 0x3 >;                    /* in zephyr/dts/arm/atmel/samd5x.dtsi:474 */
			counter-size = < 0x10 >;               /* in zephyr/dts/arm/atmel/samd5x.dtsi:475 */
		};

		/* node '/soc/tcc@42001000' defined in zephyr/dts/arm/atmel/samd5x.dtsi:478 */
		tcc3: tcc@42001000 {
			compatible = "atmel,sam0-tcc";         /* in zephyr/dts/arm/atmel/samd5x.dtsi:479 */
			reg = < 0x42001000 0x400 >;            /* in zephyr/dts/arm/atmel/samd5x.dtsi:480 */
			interrupts = < 0x65 0x0 >,
			             < 0x66 0x0 >,
			             < 0x67 0x0 >;             /* in zephyr/dts/arm/atmel/samd5x.dtsi:481 */
			clocks = < &gclk 0x1d >,
			         < &mclk 0x1c 0x4 >;           /* in zephyr/dts/arm/atmel/samd5x.dtsi:482 */
			clock-names = "GCLK",
			              "MCLK";                  /* in zephyr/dts/arm/atmel/samd5x.dtsi:483 */
			atmel,assigned-clocks = < &gclk 0x0 >; /* in zephyr/dts/arm/atmel/samd5x.dtsi:484 */
			atmel,assigned-clock-names = "GCLK";   /* in zephyr/dts/arm/atmel/samd5x.dtsi:485 */
			status = "disabled";                   /* in zephyr/dts/arm/atmel/samd5x.dtsi:486 */
			channels = < 0x2 >;                    /* in zephyr/dts/arm/atmel/samd5x.dtsi:488 */
			counter-size = < 0x10 >;               /* in zephyr/dts/arm/atmel/samd5x.dtsi:489 */
		};

		/* node '/soc/tcc@43001000' defined in zephyr/dts/arm/atmel/samd5x.dtsi:492 */
		tcc4: tcc@43001000 {
			compatible = "atmel,sam0-tcc";         /* in zephyr/dts/arm/atmel/samd5x.dtsi:493 */
			reg = < 0x43001000 0x400 >;            /* in zephyr/dts/arm/atmel/samd5x.dtsi:494 */
			interrupts = < 0x68 0x0 >,
			             < 0x69 0x0 >,
			             < 0x6a 0x0 >;             /* in zephyr/dts/arm/atmel/samd5x.dtsi:495 */
			clocks = < &gclk 0x26 >,
			         < &mclk 0x20 0x4 >;           /* in zephyr/dts/arm/atmel/samd5x.dtsi:496 */
			clock-names = "GCLK",
			              "MCLK";                  /* in zephyr/dts/arm/atmel/samd5x.dtsi:497 */
			atmel,assigned-clocks = < &gclk 0x0 >; /* in zephyr/dts/arm/atmel/samd5x.dtsi:498 */
			atmel,assigned-clock-names = "GCLK";   /* in zephyr/dts/arm/atmel/samd5x.dtsi:499 */
			status = "disabled";                   /* in zephyr/dts/arm/atmel/samd5x.dtsi:500 */
			channels = < 0x2 >;                    /* in zephyr/dts/arm/atmel/samd5x.dtsi:502 */
			counter-size = < 0x10 >;               /* in zephyr/dts/arm/atmel/samd5x.dtsi:503 */
		};

		/* node '/soc/ethernet@42000800' defined in zephyr/dts/arm/atmel/same5x.dtsi:13 */
		gmac: ethernet@42000800 {
			compatible = "atmel,sam0-gmac";            /* in zephyr/dts/arm/atmel/same5x.dtsi:14 */
			reg = < 0x42000800 0x400 >;                /* in zephyr/dts/arm/atmel/same5x.dtsi:15 */
			interrupts = < 0x54 0x0 >;                 /* in zephyr/dts/arm/atmel/same5x.dtsi:16 */
			interrupt-names = "gmac";                  /* in zephyr/dts/arm/atmel/same5x.dtsi:17 */
			num-queues = < 0x1 >;                      /* in zephyr/dts/arm/atmel/same5x.dtsi:20 */
			local-mac-address = [ 00 00 00 00 00 00 ]; /* in zephyr/dts/arm/atmel/same5x.dtsi:21 */
			status = "okay";                           /* in zephyr/boards/atmel/sam0/same54_xpro/same54_xpro.dts:133 */
			pinctrl-0 = < &gmac_rmii >;                /* in zephyr/boards/atmel/sam0/same54_xpro/same54_xpro.dts:135 */
			pinctrl-names = "default";                 /* in zephyr/boards/atmel/sam0/same54_xpro/same54_xpro.dts:136 */
			mac-eeprom = < &eeprom >;                  /* in zephyr/boards/atmel/sam0/same54_xpro/same54_xpro.dts:138 */
			phy-handle = < &phy >;                     /* in zephyr/boards/atmel/sam0/same54_xpro/same54_xpro.dts:139 */
		};

		/* node '/soc/mdio@42000800' defined in zephyr/dts/arm/atmel/same5x.dtsi:24 */
		mdio: mdio@42000800 {
			compatible = "atmel,sam-mdio"; /* in zephyr/dts/arm/atmel/same5x.dtsi:25 */
			reg = < 0x42000800 0x400 >;    /* in zephyr/dts/arm/atmel/same5x.dtsi:26 */
			#address-cells = < 0x1 >;      /* in zephyr/dts/arm/atmel/same5x.dtsi:29 */
			#size-cells = < 0x0 >;         /* in zephyr/dts/arm/atmel/same5x.dtsi:30 */
			status = "okay";               /* in zephyr/boards/atmel/sam0/same54_xpro/same54_xpro.dts:143 */
			pinctrl-0 = < &mdio_default >; /* in zephyr/boards/atmel/sam0/same54_xpro/same54_xpro.dts:145 */
			pinctrl-names = "default";     /* in zephyr/boards/atmel/sam0/same54_xpro/same54_xpro.dts:146 */

			/* node '/soc/mdio@42000800/ethernet-phy@0' defined in zephyr/boards/atmel/sam0/same54_xpro/same54_xpro.dts:148 */
			phy: ethernet-phy@0 {
				compatible = "ethernet-phy"; /* in zephyr/boards/atmel/sam0/same54_xpro/same54_xpro.dts:149 */
				status = "okay";             /* in zephyr/boards/atmel/sam0/same54_xpro/same54_xpro.dts:150 */
				reg = < 0x0 >;               /* in zephyr/boards/atmel/sam0/same54_xpro/same54_xpro.dts:151 */
				phandle = < 0xd >;           /* in zephyr/boards/atmel/sam0/same54_xpro/same54_xpro.dts:139 */
			};
		};

		/* node '/soc/can@42000000' defined in zephyr/dts/arm/atmel/same5x.dtsi:33 */
		can0: can@42000000 {
			compatible = "atmel,sam0-can";                               /* in zephyr/dts/arm/atmel/same5x.dtsi:34 */
			reg = < 0x42000000 0x400 >;                                  /* in zephyr/dts/arm/atmel/same5x.dtsi:35 */
			interrupts = < 0x4e 0x0 >,
			             < 0x4e 0x0 >;                                   /* in zephyr/dts/arm/atmel/same5x.dtsi:36 */
			interrupt-names = "int0",
			                  "int1";                                    /* in zephyr/dts/arm/atmel/same5x.dtsi:37 */
			clocks = < &gclk 0x1b >,
			         < &mclk 0x10 0x11 >;                                /* in zephyr/dts/arm/atmel/same5x.dtsi:38 */
			clock-names = "GCLK",
			              "MCLK";                                        /* in zephyr/dts/arm/atmel/same5x.dtsi:39 */
			atmel,assigned-clocks = < &gclk 0x7 >;                       /* in zephyr/dts/arm/atmel/same5x.dtsi:40 */
			atmel,assigned-clock-names = "GCLK";                         /* in zephyr/dts/arm/atmel/same5x.dtsi:41 */
			status = "disabled";                                         /* in zephyr/dts/arm/atmel/same5x.dtsi:42 */
			bosch,mram-cfg = < 0x0 0x80 0x40 0x40 0x40 0x40 0x20 0x20 >; /* in zephyr/dts/arm/atmel/same5x.dtsi:44 */
			divider = < 0x1 >;                                           /* in zephyr/dts/arm/atmel/same5x.dtsi:45 */
		};

		/* node '/soc/can@42000400' defined in zephyr/dts/arm/atmel/same5x.dtsi:48 */
		can1: can@42000400 {
			compatible = "atmel,sam0-can";                               /* in zephyr/dts/arm/atmel/same5x.dtsi:49 */
			reg = < 0x42000400 0x400 >;                                  /* in zephyr/dts/arm/atmel/same5x.dtsi:50 */
			interrupts = < 0x4f 0x0 >,
			             < 0x4f 0x0 >;                                   /* in zephyr/dts/arm/atmel/same5x.dtsi:51 */
			interrupt-names = "int0",
			                  "int1";                                    /* in zephyr/dts/arm/atmel/same5x.dtsi:52 */
			clocks = < &gclk 0x1c >,
			         < &mclk 0x10 0x12 >;                                /* in zephyr/dts/arm/atmel/same5x.dtsi:53 */
			clock-names = "GCLK",
			              "MCLK";                                        /* in zephyr/dts/arm/atmel/same5x.dtsi:54 */
			atmel,assigned-clocks = < &gclk 0x7 >;                       /* in zephyr/dts/arm/atmel/same5x.dtsi:55 */
			atmel,assigned-clock-names = "GCLK";                         /* in zephyr/dts/arm/atmel/same5x.dtsi:56 */
			status = "disabled";                                         /* in zephyr/dts/arm/atmel/same5x.dtsi:57 */
			bosch,mram-cfg = < 0x0 0x80 0x40 0x40 0x40 0x40 0x20 0x20 >; /* in zephyr/dts/arm/atmel/same5x.dtsi:59 */
			divider = < 0x1 >;                                           /* in zephyr/dts/arm/atmel/same5x.dtsi:60 */
		};
	};

	/* node '/cpus' defined in zephyr/dts/arm/atmel/samd5x.dtsi:55 */
	cpus {
		#address-cells = < 0x1 >; /* in zephyr/dts/arm/atmel/samd5x.dtsi:56 */
		#size-cells = < 0x0 >;    /* in zephyr/dts/arm/atmel/samd5x.dtsi:57 */

		/* node '/cpus/cpu@0' defined in zephyr/dts/arm/atmel/samd5x.dtsi:59 */
		cpu0: cpu@0 {
			compatible = "arm,cortex-m4f";   /* in zephyr/dts/arm/atmel/samd5x.dtsi:60 */
			reg = < 0x0 >;                   /* in zephyr/dts/arm/atmel/samd5x.dtsi:61 */
			#address-cells = < 0x1 >;        /* in zephyr/dts/arm/atmel/samd5x.dtsi:63 */
			#size-cells = < 0x1 >;           /* in zephyr/dts/arm/atmel/samd5x.dtsi:64 */
			device_type = "cpu";             /* in zephyr/dts/arm/atmel/samd5x.dtsi:66 */
			clock-frequency = < 0x7270e00 >; /* in zephyr/boards/atmel/sam0/same54_xpro/same54_xpro.dts:58 */

			/* node '/cpus/cpu@0/mpu@e000ed90' defined in zephyr/dts/arm/atmel/samd5x.dtsi:68 */
			mpu: mpu@e000ed90 {
				compatible = "arm,armv7m-mpu"; /* in zephyr/dts/arm/atmel/samd5x.dtsi:69 */
				reg = < 0xe000ed90 0x40 >;     /* in zephyr/dts/arm/atmel/samd5x.dtsi:70 */
			};
		};
	};

	/* node '/leds' defined in zephyr/boards/atmel/sam0/same54_xpro/same54_xpro.dts:32 */
	leds {
		compatible = "gpio-leds"; /* in temperature-web-app/app/boards/same54_xpro.overlay:46 */

		/* node '/leds/led_0' defined in zephyr/boards/atmel/sam0/same54_xpro/same54_xpro.dts:34 */
		led0: led_0 {
			gpios = < &portc 0x12 0x1 >; /* in zephyr/boards/atmel/sam0/same54_xpro/same54_xpro.dts:35 */
			label = "Yellow LED";        /* in zephyr/boards/atmel/sam0/same54_xpro/same54_xpro.dts:36 */
		};

		/* node '/leds/io1_led' defined in temperature-web-app/app/boards/same54_xpro.overlay:47 */
		io1_led: io1_led {
			gpios = < &portb 0x8 0x1 >; /* in temperature-web-app/app/boards/same54_xpro.overlay:48 */
			label = "IO1 Yellow LED";   /* in temperature-web-app/app/boards/same54_xpro.overlay:49 */
		};
	};

	/* node '/pwmleds' defined in zephyr/boards/atmel/sam0/same54_xpro/same54_xpro.dts:40 */
	pwmleds {
		compatible = "pwm-leds"; /* in zephyr/boards/atmel/sam0/same54_xpro/same54_xpro.dts:41 */

		/* node '/pwmleds/pwm_led_0' defined in zephyr/boards/atmel/sam0/same54_xpro/same54_xpro.dts:42 */
		pwm_led0: pwm_led_0 {
			pwms = < &tcc0 0x2 0x1312d00 >; /* in zephyr/boards/atmel/sam0/same54_xpro/same54_xpro.dts:43 */
		};
	};

	/* node '/buttons' defined in zephyr/boards/atmel/sam0/same54_xpro/same54_xpro.dts:47 */
	buttons {
		compatible = "gpio-keys"; /* in zephyr/boards/atmel/sam0/same54_xpro/same54_xpro.dts:48 */

		/* node '/buttons/button_0' defined in zephyr/boards/atmel/sam0/same54_xpro/same54_xpro.dts:49 */
		button0: button_0 {
			gpios = < &portb 0x1f 0x11 >; /* in zephyr/boards/atmel/sam0/same54_xpro/same54_xpro.dts:50 */
			label = "SW0";                /* in zephyr/boards/atmel/sam0/same54_xpro/same54_xpro.dts:51 */
			zephyr,code = < 0xb >;        /* in zephyr/boards/atmel/sam0/same54_xpro/same54_xpro.dts:52 */
		};
	};
};
